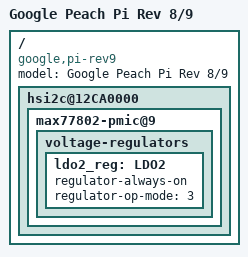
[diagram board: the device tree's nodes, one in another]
/*
 * Google Peach Pi Rev 8/9 board device tree source
 *
 * Copyright (c) 2013 Google, Inc
 *
 * This program is free software; you can redistribute it and/or modify
 * it under the terms of the GNU General Public License version 2 as
 * published by the Free Software Foundation.
 */

/dts-v1/;
#include "exynos5420.dtsi"
#include "exynos5420-peach.dtsi"
#include "exynos5420-peach-pi.dtsi"

/ {
	model = "Google Peach Pi Rev 8/9";

	compatible = "google,pi-rev9", "google,pi-rev8",
		"google,pi", "google,peach", "samsung,exynos5420";

	hsi2c@12CA0000 {
		max77802-pmic@9 {
			voltage-regulators {
				/* This is used for SDRAM on PoP */
				ldo2_reg: LDO2 {
					regulator-always-on;
					regulator-op-mode = <3>;
				};
			};
		};
	};
};
